# iorx610 register map
Registers from a debugger description file.
Registers are 8-bit, access not given, no defined reset value unless marked. A register's access mark holds for its fields unless they carry their own. Addresses are absolute; registers are grouped by the start of their names; lines under a group give offsets from that group; [hi:lo] are bit positions; {n}, {i} and the like mark numbered series; 'fields as' and 'values as' point back to an identical list; <NAME> marks a mode.

## SFR (part 1 of 2)
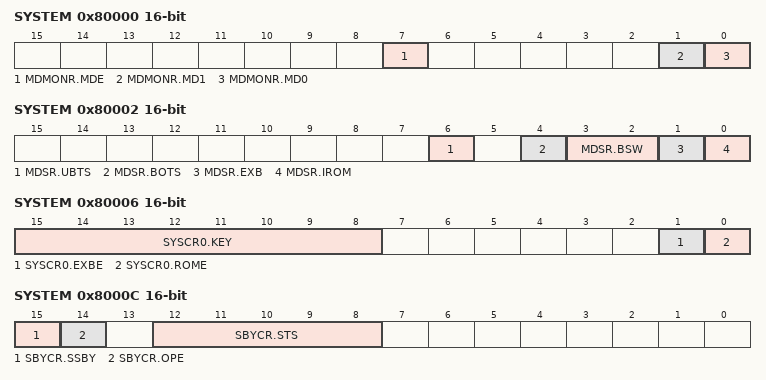
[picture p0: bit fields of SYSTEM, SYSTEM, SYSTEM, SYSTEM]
0x80000 SYSTEM 16-bit
  [7] MDMONR.MDE, [1] MDMONR.MD1, [0] MDMONR.MD0
0x80002 SYSTEM 16-bit
  [6] MDSR.UBTS, [4] MDSR.BOTS, [3:2] MDSR.BSW, [1] MDSR.EXB, [0] MDSR.IROM
0x80006 SYSTEM 16-bit
  [15:8] SYSCR0.KEY, [1] SYSCR0.EXBE, [0] SYSCR0.ROME
0x80008 SYSTEM 16-bit
  [0] SYSCR1.RAME
0x8000C SYSTEM 16-bit
  [15] SBYCR.SSBY, [14] SBYCR.OPE, [12:8] SBYCR.STS
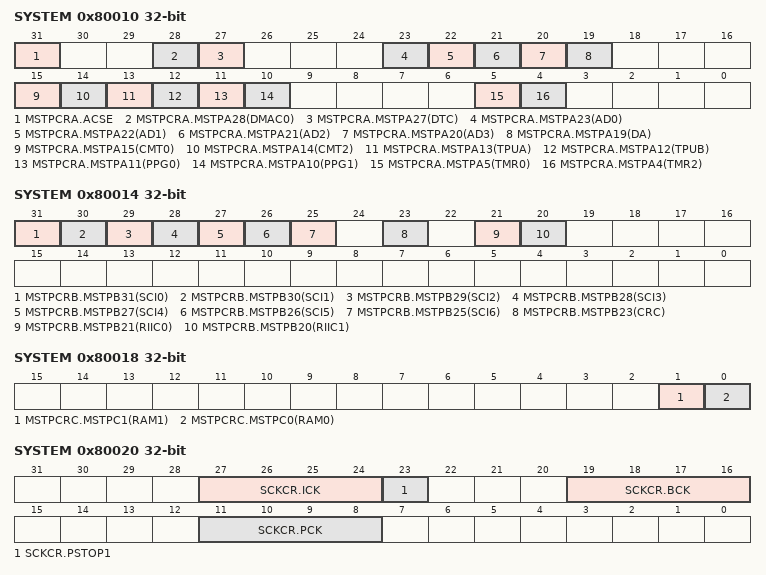
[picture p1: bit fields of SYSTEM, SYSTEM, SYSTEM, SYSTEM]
0x80010 SYSTEM 32-bit
  [31] MSTPCRA.ACSE, [28] MSTPCRA.MSTPA28(DMAC0), [27] MSTPCRA.MSTPA27(DTC), [23] MSTPCRA.MSTPA23(AD0), [22] MSTPCRA.MSTPA22(AD1), [21] MSTPCRA.MSTPA21(AD2), [20] MSTPCRA.MSTPA20(AD3), [19] MSTPCRA.MSTPA19(DA), [15] MSTPCRA.MSTPA15(CMT0), [14] MSTPCRA.MSTPA14(CMT2), [13] MSTPCRA.MSTPA13(TPUA), [12] MSTPCRA.MSTPA12(TPUB), [11] MSTPCRA.MSTPA11(PPG0), [10] MSTPCRA.MSTPA10(PPG1), [5] MSTPCRA.MSTPA5(TMR0), [4] MSTPCRA.MSTPA4(TMR2)
0x80014 SYSTEM 32-bit
  [31] MSTPCRB.MSTPB31(SCI0), [30] MSTPCRB.MSTPB30(SCI1), [29] MSTPCRB.MSTPB29(SCI2), [28] MSTPCRB.MSTPB28(SCI3), [27] MSTPCRB.MSTPB27(SCI4), [26] MSTPCRB.MSTPB26(SCI5), [25] MSTPCRB.MSTPB25(SCI6), [23] MSTPCRB.MSTPB23(CRC), [21] MSTPCRB.MSTPB21(RIIC0), [20] MSTPCRB.MSTPB20(RIIC1)
0x80018 SYSTEM 32-bit
  [1] MSTPCRC.MSTPC1(RAM1), [0] MSTPCRC.MSTPC0(RAM0)
0x80020 SYSTEM 32-bit
  [27:24] SCKCR.ICK, [23] SCKCR.PSTOP1, [19:16] SCKCR.BCK, [11:8] SCKCR.PCK
0x81300 BSC
  [0] BERCLR.STSCLR
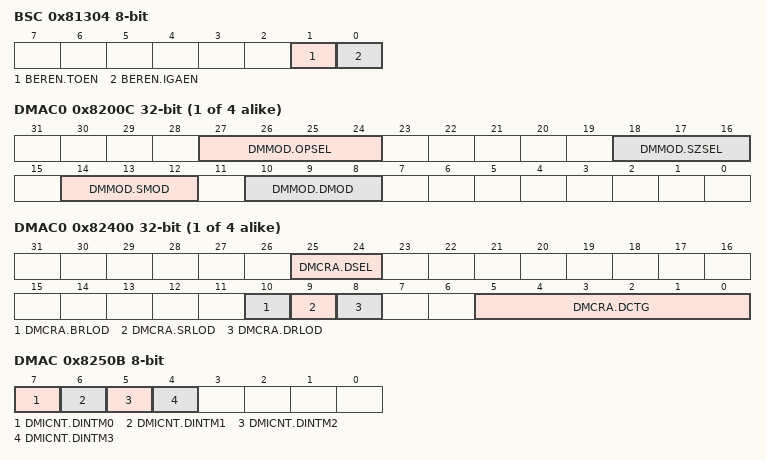
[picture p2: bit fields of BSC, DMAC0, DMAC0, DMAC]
0x81304 BSC
  [1] BEREN.TOEN, [0] BEREN.IGAEN
0x81306 BSC
  [0] BERIE.CPEN
{0x8200C+0x10*i} DMAC{i} 32-bit (i=0..3)
  [27:24] DMMOD.OPSEL, [18:16] DMMOD.SZSEL, [14:12] DMMOD.SMOD, [10:8] DMMOD.DMOD
{0x82400+8i} DMAC{i} 32-bit (i=0..3)
  [25:24] DMCRA.DSEL, [10] DMCRA.BRLOD, [9] DMCRA.SRLOD, [8] DMCRA.DRLOD, [5:0] DMCRA.DCTG
{0x82404+8i} DMAC{i} (i=0..3)
  [0] DMCRB.DSCLR
{0x82405+8i} DMAC{i} (i=0..3)
  [0] DMCRC.ECLR
{0x82406+8i} DMAC{i} (i=0..3)
  [0] DMCRD.DREQ
{0x82407+8i} DMAC{i} (i=0..3)
  [0] DMCRE.DEN
0x82502 DMAC
  [0] DMSCNT.DMST
0x8250B DMAC
  [7-n] DMICNT.DINTM{n} (n=0..3)
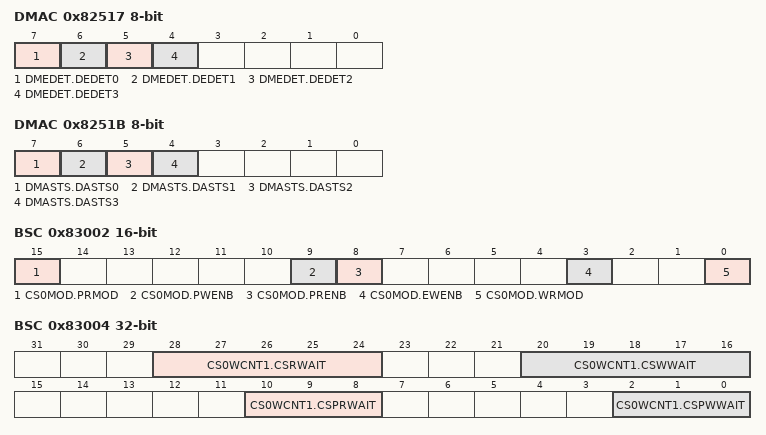
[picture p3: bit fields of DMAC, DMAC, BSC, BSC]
0x82517 DMAC
  [7-n] DMEDET.DEDET{n} (n=0..3)
0x8251B DMAC
  [7-n] DMASTS.DASTS{n} (n=0..3)
0x83002 BSC 16-bit
  [15] CS0MOD.PRMOD, [9] CS0MOD.PWENB, [8] CS0MOD.PRENB, [3] CS0MOD.EWENB, [0] CS0MOD.WRMOD
0x83004 BSC 32-bit
  [28:24] CS0WCNT1.CSRWAIT, [20:16] CS0WCNT1.CSWWAIT, [10:8] CS0WCNT1.CSPRWAIT, [2:0] CS0WCNT1.CSPWWAIT
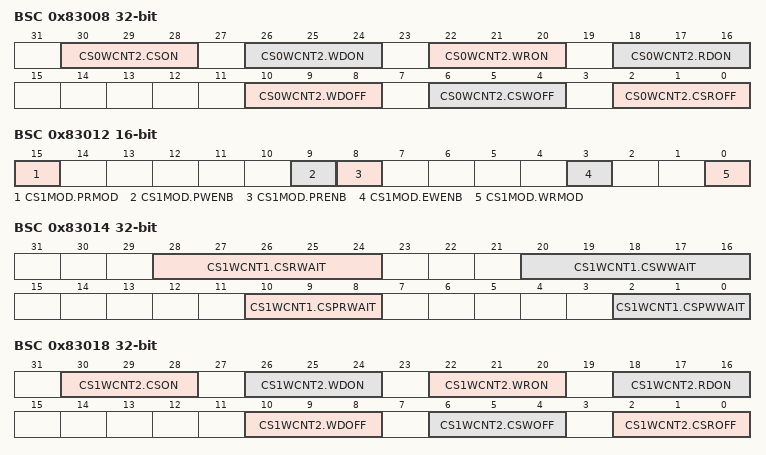
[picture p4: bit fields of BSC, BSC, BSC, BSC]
0x83008 BSC 32-bit
  [30:28] CS0WCNT2.CSON, [26:24] CS0WCNT2.WDON, [22:20] CS0WCNT2.WRON, [18:16] CS0WCNT2.RDON, [10:8] CS0WCNT2.WDOFF, [6:4] CS0WCNT2.CSWOFF, [2:0] CS0WCNT2.CSROFF
0x83012 BSC 16-bit
  [15] CS1MOD.PRMOD, [9] CS1MOD.PWENB, [8] CS1MOD.PRENB, [3] CS1MOD.EWENB, [0] CS1MOD.WRMOD
0x83014 BSC 32-bit
  [28:24] CS1WCNT1.CSRWAIT, [20:16] CS1WCNT1.CSWWAIT, [10:8] CS1WCNT1.CSPRWAIT, [2:0] CS1WCNT1.CSPWWAIT
0x83018 BSC 32-bit
  [30:28] CS1WCNT2.CSON, [26:24] CS1WCNT2.WDON, [22:20] CS1WCNT2.WRON, [18:16] CS1WCNT2.RDON, [10:8] CS1WCNT2.WDOFF, [6:4] CS1WCNT2.CSWOFF, [2:0] CS1WCNT2.CSROFF
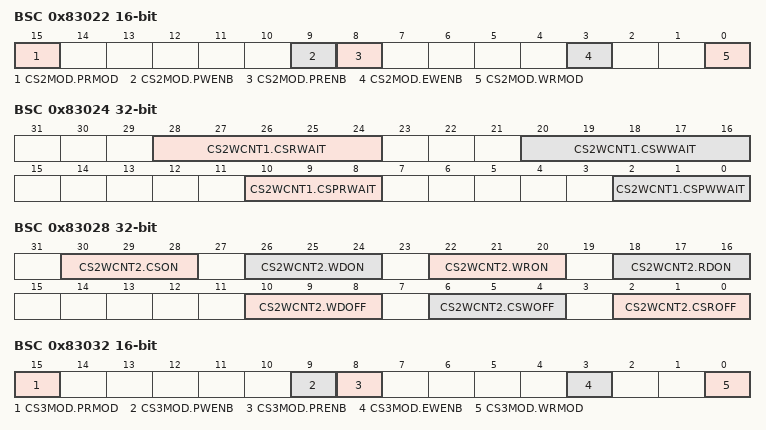
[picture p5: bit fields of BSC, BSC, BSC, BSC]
0x83022 BSC 16-bit
  [15] CS2MOD.PRMOD, [9] CS2MOD.PWENB, [8] CS2MOD.PRENB, [3] CS2MOD.EWENB, [0] CS2MOD.WRMOD
0x83024 BSC 32-bit
  [28:24] CS2WCNT1.CSRWAIT, [20:16] CS2WCNT1.CSWWAIT, [10:8] CS2WCNT1.CSPRWAIT, [2:0] CS2WCNT1.CSPWWAIT
0x83028 BSC 32-bit
  [30:28] CS2WCNT2.CSON, [26:24] CS2WCNT2.WDON, [22:20] CS2WCNT2.WRON, [18:16] CS2WCNT2.RDON, [10:8] CS2WCNT2.WDOFF, [6:4] CS2WCNT2.CSWOFF, [2:0] CS2WCNT2.CSROFF
0x83032 BSC 16-bit
  [15] CS3MOD.PRMOD, [9] CS3MOD.PWENB, [8] CS3MOD.PRENB, [3] CS3MOD.EWENB, [0] CS3MOD.WRMOD
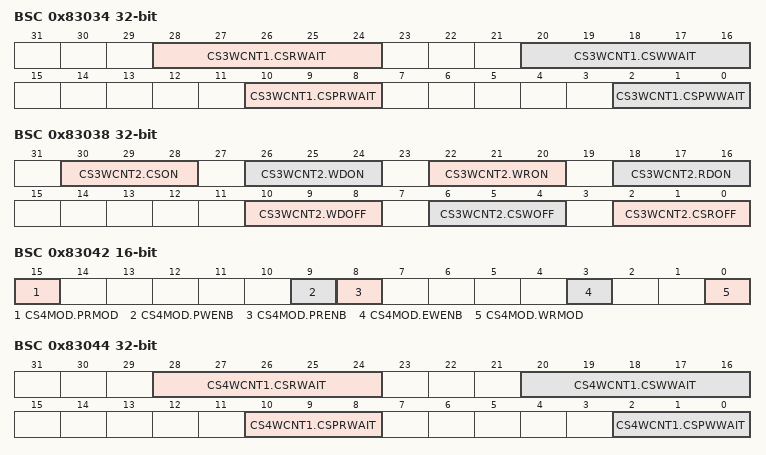
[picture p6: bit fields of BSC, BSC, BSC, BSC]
0x83034 BSC 32-bit
  [28:24] CS3WCNT1.CSRWAIT, [20:16] CS3WCNT1.CSWWAIT, [10:8] CS3WCNT1.CSPRWAIT, [2:0] CS3WCNT1.CSPWWAIT
0x83038 BSC 32-bit
  [30:28] CS3WCNT2.CSON, [26:24] CS3WCNT2.WDON, [22:20] CS3WCNT2.WRON, [18:16] CS3WCNT2.RDON, [10:8] CS3WCNT2.WDOFF, [6:4] CS3WCNT2.CSWOFF, [2:0] CS3WCNT2.CSROFF
0x83042 BSC 16-bit
  [15] CS4MOD.PRMOD, [9] CS4MOD.PWENB, [8] CS4MOD.PRENB, [3] CS4MOD.EWENB, [0] CS4MOD.WRMOD
0x83044 BSC 32-bit
  [28:24] CS4WCNT1.CSRWAIT, [20:16] CS4WCNT1.CSWWAIT, [10:8] CS4WCNT1.CSPRWAIT, [2:0] CS4WCNT1.CSPWWAIT
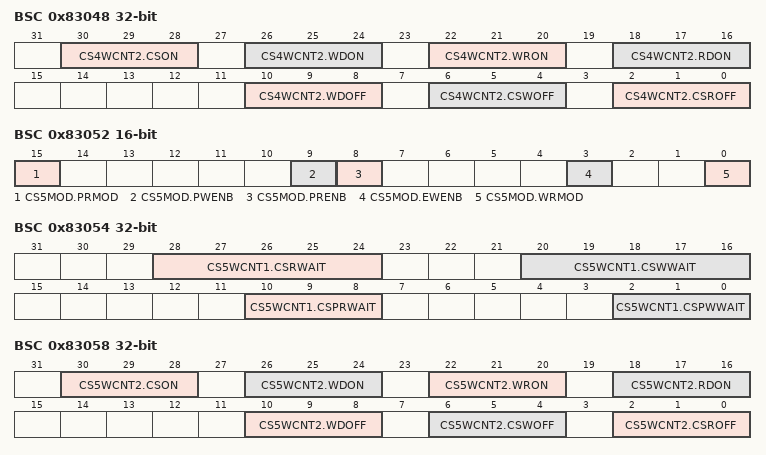
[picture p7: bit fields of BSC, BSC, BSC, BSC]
0x83048 BSC 32-bit
  [30:28] CS4WCNT2.CSON, [26:24] CS4WCNT2.WDON, [22:20] CS4WCNT2.WRON, [18:16] CS4WCNT2.RDON, [10:8] CS4WCNT2.WDOFF, [6:4] CS4WCNT2.CSWOFF, [2:0] CS4WCNT2.CSROFF
0x83052 BSC 16-bit
  [15] CS5MOD.PRMOD, [9] CS5MOD.PWENB, [8] CS5MOD.PRENB, [3] CS5MOD.EWENB, [0] CS5MOD.WRMOD
0x83054 BSC 32-bit
  [28:24] CS5WCNT1.CSRWAIT, [20:16] CS5WCNT1.CSWWAIT, [10:8] CS5WCNT1.CSPRWAIT, [2:0] CS5WCNT1.CSPWWAIT
0x83058 BSC 32-bit
  [30:28] CS5WCNT2.CSON, [26:24] CS5WCNT2.WDON, [22:20] CS5WCNT2.WRON, [18:16] CS5WCNT2.RDON, [10:8] CS5WCNT2.WDOFF, [6:4] CS5WCNT2.CSWOFF, [2:0] CS5WCNT2.CSROFF
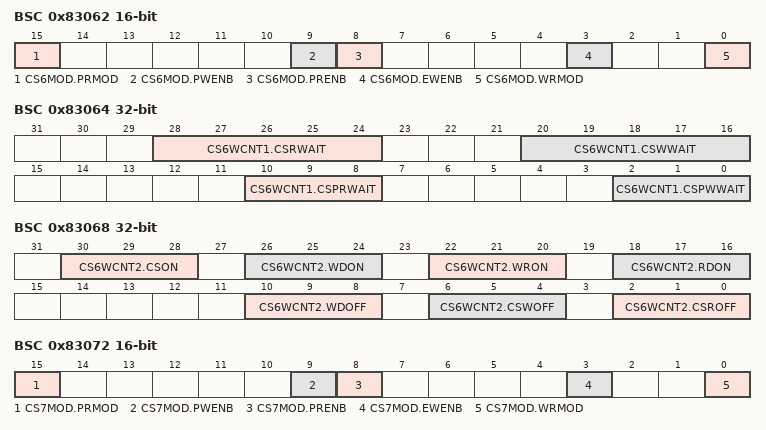
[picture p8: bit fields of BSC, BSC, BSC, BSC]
0x83062 BSC 16-bit
  [15] CS6MOD.PRMOD, [9] CS6MOD.PWENB, [8] CS6MOD.PRENB, [3] CS6MOD.EWENB, [0] CS6MOD.WRMOD
0x83064 BSC 32-bit
  [28:24] CS6WCNT1.CSRWAIT, [20:16] CS6WCNT1.CSWWAIT, [10:8] CS6WCNT1.CSPRWAIT, [2:0] CS6WCNT1.CSPWWAIT
0x83068 BSC 32-bit
  [30:28] CS6WCNT2.CSON, [26:24] CS6WCNT2.WDON, [22:20] CS6WCNT2.WRON, [18:16] CS6WCNT2.RDON, [10:8] CS6WCNT2.WDOFF, [6:4] CS6WCNT2.CSWOFF, [2:0] CS6WCNT2.CSROFF
0x83072 BSC 16-bit
  [15] CS7MOD.PRMOD, [9] CS7MOD.PWENB, [8] CS7MOD.PRENB, [3] CS7MOD.EWENB, [0] CS7MOD.WRMOD
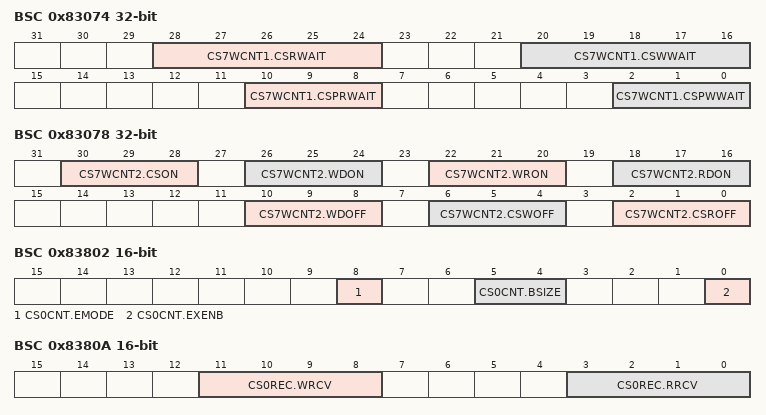
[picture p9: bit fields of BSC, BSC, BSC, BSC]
0x83074 BSC 32-bit
  [28:24] CS7WCNT1.CSRWAIT, [20:16] CS7WCNT1.CSWWAIT, [10:8] CS7WCNT1.CSPRWAIT, [2:0] CS7WCNT1.CSPWWAIT
0x83078 BSC 32-bit
  [30:28] CS7WCNT2.CSON, [26:24] CS7WCNT2.WDON, [22:20] CS7WCNT2.WRON, [18:16] CS7WCNT2.RDON, [10:8] CS7WCNT2.WDOFF, [6:4] CS7WCNT2.CSWOFF, [2:0] CS7WCNT2.CSROFF
0x83802 BSC 16-bit
  [8] CS0CNT.EMODE, [5:4] CS0CNT.BSIZE, [0] CS0CNT.EXENB
0x8380A BSC 16-bit
  [11:8] CS0REC.WRCV, [3:0] CS0REC.RRCV
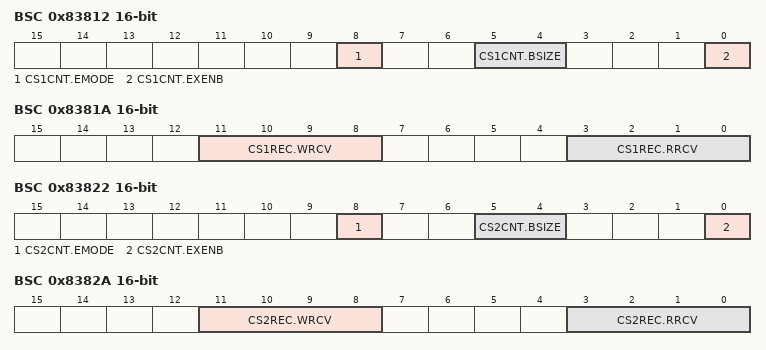
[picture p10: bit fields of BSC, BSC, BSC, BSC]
0x83812 BSC 16-bit
  [8] CS1CNT.EMODE, [5:4] CS1CNT.BSIZE, [0] CS1CNT.EXENB
0x8381A BSC 16-bit
  [11:8] CS1REC.WRCV, [3:0] CS1REC.RRCV
0x83822 BSC 16-bit
  [8] CS2CNT.EMODE, [5:4] CS2CNT.BSIZE, [0] CS2CNT.EXENB
0x8382A BSC 16-bit
  [11:8] CS2REC.WRCV, [3:0] CS2REC.RRCV
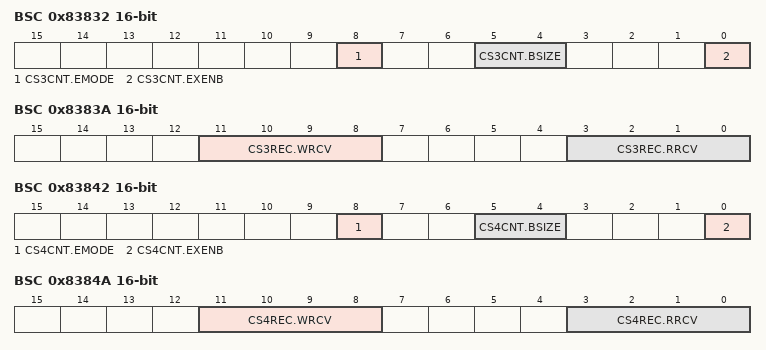
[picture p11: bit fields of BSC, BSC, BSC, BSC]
0x83832 BSC 16-bit
  [8] CS3CNT.EMODE, [5:4] CS3CNT.BSIZE, [0] CS3CNT.EXENB
0x8383A BSC 16-bit
  [11:8] CS3REC.WRCV, [3:0] CS3REC.RRCV
0x83842 BSC 16-bit
  [8] CS4CNT.EMODE, [5:4] CS4CNT.BSIZE, [0] CS4CNT.EXENB
0x8384A BSC 16-bit
  [11:8] CS4REC.WRCV, [3:0] CS4REC.RRCV
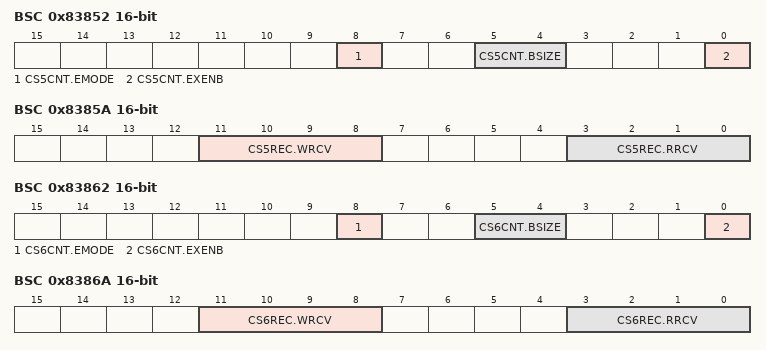
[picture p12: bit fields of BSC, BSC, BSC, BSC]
0x83852 BSC 16-bit
  [8] CS5CNT.EMODE, [5:4] CS5CNT.BSIZE, [0] CS5CNT.EXENB
0x8385A BSC 16-bit
  [11:8] CS5REC.WRCV, [3:0] CS5REC.RRCV
0x83862 BSC 16-bit
  [8] CS6CNT.EMODE, [5:4] CS6CNT.BSIZE, [0] CS6CNT.EXENB
0x8386A BSC 16-bit
  [11:8] CS6REC.WRCV, [3:0] CS6REC.RRCV
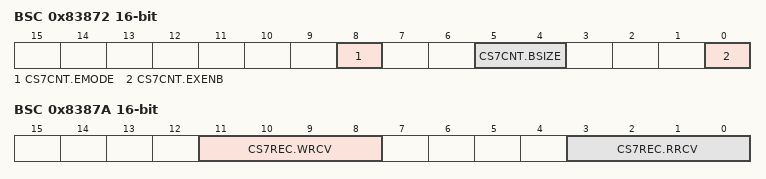
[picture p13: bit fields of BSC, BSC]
0x83872 BSC 16-bit
  [8] CS7CNT.EMODE, [5:4] CS7CNT.BSIZE, [0] CS7CNT.EXENB
0x8387A BSC 16-bit
  [11:8] CS7REC.WRCV, [3:0] CS7REC.RRCV
0x87000 ICU
  [0] IR[0].IR
0x87001 ICU
  [0] IR[1].IR
0x87002 ICU
  [0] IR[2].IR
0x87003 ICU
  [0] IR[3].IR
0x87004 ICU
  [0] IR[4].IR
0x87005 ICU
  [0] IR[5].IR
0x87006 ICU
  [0] IR[6].IR
0x87007 ICU
  [0] IR[7].IR
0x87008 ICU
  [0] IR[8].IR
0x87009 ICU
  [0] IR[9].IR
0x8700A ICU
  [0] IR[10].IR
0x8700B ICU
  [0] IR[11].IR
0x8700C ICU
  [0] IR[12].IR
0x8700D ICU
  [0] IR[13].IR
0x8700E ICU
  [0] IR[14].IR
0x8700F ICU
  [0] IR[15].IR
0x87010 ICU
  [0] IR[16](BSC,BUSERR).IR
0x87011 ICU
  [0] IR[17].IR
0x87012 ICU
  [0] IR[18].IR
0x87013 ICU
  [0] IR[19].IR
0x87014 ICU
  [0] IR[20].IR
0x87015 ICU
  [0] IR[21](FCU,FIFERR).IR
0x87016 ICU
  [0] IR[22].IR
0x87017 ICU
  [0] IR[23](FCU,FRDYI).IR
0x87018 ICU
  [0] IR[24].IR
0x87019 ICU
  [0] IR[25].IR
0x8701A ICU
  [0] IR[26].IR
0x8701B ICU
  [0] IR[27].IR
0x8701C ICU
  [0] IR[28](CMT0,CMI0).IR
0x8701D ICU
  [0] IR[29](CMT1,CMI1).IR
0x8701E ICU
  [0] IR[30](CMT2,CMI2).IR
0x8701F ICU
  [0] IR[31](CMT3,CMI3).IR
0x87020 ICU
  [0] IR[32].IR
0x87021 ICU
  [0] IR[33].IR
0x87022 ICU
  [0] IR[34].IR
0x87023 ICU
  [0] IR[35].IR
0x87024 ICU
  [0] IR[36].IR
0x87025 ICU
  [0] IR[37].IR
0x87026 ICU
  [0] IR[38].IR
0x87027 ICU
  [0] IR[39].IR
0x87028 ICU
  [0] IR[40].IR
0x87029 ICU
  [0] IR[41].IR
0x8702A ICU
  [0] IR[42].IR
0x8702B ICU
  [0] IR[43].IR
0x8702C ICU
  [0] IR[44].IR
0x8702D ICU
  [0] IR[45].IR
0x8702E ICU
  [0] IR[46].IR
0x8702F ICU
  [0] IR[47].IR
0x87030 ICU
  [0] IR[48].IR
0x87031 ICU
  [0] IR[49].IR
0x87032 ICU
  [0] IR[50].IR
0x87033 ICU
  [0] IR[51].IR
0x87034 ICU
  [0] IR[52].IR
0x87035 ICU
  [0] IR[53].IR
0x87036 ICU
  [0] IR[54].IR
0x87037 ICU
  [0] IR[55].IR
0x87038 ICU
  [0] IR[56].IR
0x87039 ICU
  [0] IR[57].IR
0x8703A ICU
  [0] IR[58].IR
0x8703B ICU
  [0] IR[59].IR
0x8703C ICU
  [0] IR[60].IR
0x8703D ICU
  [0] IR[61].IR
0x8703E ICU
  [0] IR[62].IR
0x8703F ICU
  [0] IR[63].IR
0x87040 ICU
  [0] IR[64](ICU,IRQ0).IR
0x87041 ICU
  [0] IR[65](ICU,IRQ1).IR
0x87042 ICU
  [0] IR[66](ICU,IRQ2).IR
0x87043 ICU
  [0] IR[67](ICU,IRQ3).IR
0x87044 ICU
  [0] IR[68](ICU,IRQ4).IR
0x87045 ICU
  [0] IR[69](ICU,IRQ5).IR
0x87046 ICU
  [0] IR[70](ICU,IRQ6).IR
0x87047 ICU
  [0] IR[71](ICU,IRQ7).IR
0x87048 ICU
  [0] IR[72](ICU,IRQ8).IR
0x87049 ICU
  [0] IR[73](ICU,IRQ9).IR
0x8704A ICU
  [0] IR[74](ICU,IRQ10).IR
0x8704B ICU
  [0] IR[75](ICU,IRQ11).IR
0x8704C ICU
  [0] IR[76](ICU,IRQ12).IR
0x8704D ICU
  [0] IR[77](ICU,IRQ13).IR
0x8704E ICU
  [0] IR[78](ICU,IRQ14).IR
0x8704F ICU
  [0] IR[79](ICU,IRQ15).IR
0x87050 ICU
  [0] IR[80].IR
0x87051 ICU
  [0] IR[81].IR
0x87052 ICU
  [0] IR[82].IR
0x87053 ICU
  [0] IR[83].IR
0x87054 ICU
  [0] IR[84].IR
0x87055 ICU
  [0] IR[85].IR
0x87056 ICU
  [0] IR[86].IR
0x87057 ICU
  [0] IR[87].IR
0x87058 ICU
  [0] IR[88].IR
0x87059 ICU
  [0] IR[89].IR
0x8705A ICU
  [0] IR[90].IR
0x8705B ICU
  [0] IR[91].IR
0x8705C ICU
  [0] IR[92].IR
0x8705D ICU
  [0] IR[93].IR
0x8705E ICU
  [0] IR[94].IR
0x8705F ICU
  [0] IR[95].IR
0x87060 ICU
  [0] IR[96](WDT,WOVI).IR
0x87061 ICU
  [0] IR[97].IR
0x87062 ICU
  [0] IR[98](AD0,ADI0).IR
0x87063 ICU
  [0] IR[99](AD1,ADI1).IR
0x87064 ICU
  [0] IR[100](AD2,ADI2).IR
0x87065 ICU
  [0] IR[101](AD3,ADI3).IR
0x87066 ICU
  [0] IR[102].IR
0x87067 ICU
  [0] IR[103].IR
0x87068 ICU
  [0] IR[104](TPU0,TGI0A).IR
0x87069 ICU
  [0] IR[105](TPU0,TGI0B).IR
0x8706A ICU
  [0] IR[106](TPU0,TGI0C).IR
0x8706B ICU
  [0] IR[107](TPU0,TGI0D).IR
0x8706C ICU
  [0] IR[108](TPU0,TCI0V).IR
0x8706D ICU
  [0] IR[109].IR
0x8706E ICU
  [0] IR[110].IR
0x8706F ICU
  [0] IR[111](TPU1,TGI1A).IR
0x87070 ICU
  [0] IR[112](TPU1,TGI1B).IR
0x87071 ICU
  [0] IR[113].IR
0x87072 ICU
  [0] IR[114].IR
0x87073 ICU
  [0] IR[115](TPU1,TCI1V).IR
0x87074 ICU
  [0] IR[116](TPU1,TCI1U).IR
0x87075 ICU
  [0] IR[117](TPU2,TGI2A).IR
0x87076 ICU
  [0] IR[118](TPU2,TGI2B).IR
0x87077 ICU
  [0] IR[119].IR
0x87078 ICU
  [0] IR[120](TPU2,TCI2V).IR
0x87079 ICU
  [0] IR[121](TPU2,TCI2U).IR
0x8707A ICU
  [0] IR[122](TPU3,TGI3A).IR
0x8707B ICU
  [0] IR[123](TPU3,TGI3B).IR
0x8707C ICU
  [0] IR[124](TPU3,TGI3C).IR
0x8707D ICU
  [0] IR[125](TPU3,TGI3D).IR
0x8707E ICU
  [0] IR[126](TPU3,TCI3V).IR
0x8707F ICU
  [0] IR[127](TPU4,TGI4A).IR
0x87080 ICU
  [0] IR[128](TPU4,TGI4B).IR
0x87081 ICU
  [0] IR[129].IR
0x87082 ICU
  [0] IR[130].IR
0x87083 ICU
  [0] IR[131](TPU4,TCI4V).IR
0x87084 ICU
  [0] IR[132](TPU4,TCI4U).IR
0x87085 ICU
  [0] IR[133](TPU5,TGI5A).IR
0x87086 ICU
  [0] IR[134](TPU5,TGI5B).IR
0x87087 ICU
  [0] IR[135].IR
0x87088 ICU
  [0] IR[136](TPU5,TCI5V).IR
0x87089 ICU
  [0] IR[137](TPU5,TCI5U).IR
0x8708A ICU
  [0] IR[138](TPU6,TGI6A).IR
0x8708B ICU
  [0] IR[139](TPU6,TGI6B).IR
0x8708C ICU
  [0] IR[140](TPU6,TGI6C).IR
0x8708D ICU
  [0] IR[141](TPU6,TGI6D).IR
0x8708E ICU
  [0] IR[142](TPU6,TCI6V).IR
0x8708F ICU
  [0] IR[143].IR
0x87090 ICU
  [0] IR[144].IR
0x87091 ICU
  [0] IR[145](TPU7,TGI7A).IR
0x87092 ICU
  [0] IR[146](TPU7,TGI7B).IR
0x87093 ICU
  [0] IR[147].IR
0x87094 ICU
  [0] IR[148].IR
0x87095 ICU
  [0] IR[149](TPU7,TCI7V).IR
0x87096 ICU
  [0] IR[150](TPU7,TCI7U).IR
0x87097 ICU
  [0] IR[151](TPU8,TGI8A).IR
0x87098 ICU
  [0] IR[152](TPU8,TGI8B).IR
0x87099 ICU
  [0] IR[153].IR
0x8709A ICU
  [0] IR[154](TPU8,TCI8V).IR
0x8709B ICU
  [0] IR[155](TPU8,TCI8U).IR
0x8709C ICU
  [0] IR[156](TPU9,TGI9A).IR
0x8709D ICU
  [0] IR[157](TPU9,TGI9B).IR
0x8709E ICU
  [0] IR[158](TPU9,TGI9C).IR
0x8709F ICU
  [0] IR[159](TPU9,TGI9D).IR
0x870A0 ICU
  [0] IR[160](TPU9,TCI9V).IR
0x870A1 ICU
  [0] IR[161](TPU10,TGI10A).IR
0x870A2 ICU
  [0] IR[162](TPU10,TGI10B).IR
0x870A3 ICU
  [0] IR[163].IR
0x870A4 ICU
  [0] IR[164].IR
0x870A5 ICU
  [0] IR[165](TPU10,TCI10V).IR
0x870A6 ICU
  [0] IR[166](TPU10,TCI10U).IR
0x870A7 ICU
  [0] IR[167](TPU11,TGI11A).IR
0x870A8 ICU
  [0] IR[168](TPU11,TGI11B).IR
0x870A9 ICU
  [0] IR[169].IR
0x870AA ICU
  [0] IR[170](TPU11,TCI11V).IR
0x870AB ICU
  [0] IR[171](TPU11,TCI11U).IR
0x870AC ICU
  [0] IR[172].IR
0x870AD ICU
  [0] IR[173].IR
0x870AE ICU
  [0] IR[174](TMR0,CMIA0).IR
0x870AF ICU
  [0] IR[175](TMR0,CMIB0).IR
0x870B0 ICU
  [0] IR[176](TMR0,OVI0).IR
0x870B1 ICU
  [0] IR[177](TMR1,CMIA1).IR
0x870B2 ICU
  [0] IR[178](TMR1,CMIB1).IR
0x870B3 ICU
  [0] IR[179](TMR1,OVI1).IR
0x870B4 ICU
  [0] IR[180](TMR2,CMIA2).IR
0x870B5 ICU
  [0] IR[181](TMR2,CMIB2).IR
0x870B6 ICU
  [0] IR[182](TMR2,OVI2).IR
0x870B7 ICU
  [0] IR[183](TMR3,CMIA3).IR
0x870B8 ICU
  [0] IR[184](TMR3,CMIB3).IR
0x870B9 ICU
  [0] IR[185](TMR3,OVI3).IR
0x870BA ICU
  [0] IR[186].IR
0x870BB ICU
  [0] IR[187].IR
0x870BC ICU
  [0] IR[188].IR
0x870BD ICU
  [0] IR[189].IR
0x870BE ICU
  [0] IR[190].IR
0x870BF ICU
  [0] IR[191].IR
0x870C0 ICU
  [0] IR[192].IR
0x870C1 ICU
  [0] IR[193].IR
0x870C2 ICU
  [0] IR[194].IR
0x870C3 ICU
  [0] IR[195].IR
0x870C4 ICU
  [0] IR[196].IR
0x870C5 ICU
  [0] IR[197].IR
0x870C6 ICU
  [0] IR[198](DMAC,DMTEND0).IR
0x870C7 ICU
  [0] IR[199](DMAC,DMTEND1).IR
0x870C8 ICU
  [0] IR[200](DMAC,DMTEND2).IR
0x870C9 ICU
  [0] IR[201](DMAC,DMTEND3).IR
0x870CA ICU
  [0] IR[202].IR
0x870CB ICU
  [0] IR[203].IR
0x870CC ICU
  [0] IR[204].IR
0x870CD ICU
  [0] IR[205].IR
0x870CE ICU
  [0] IR[206].IR
0x870CF ICU
  [0] IR[207].IR
0x870D0 ICU
  [0] IR[208].IR
0x870D1 ICU
  [0] IR[209].IR
0x870D2 ICU
  [0] IR[210].IR
0x870D3 ICU
  [0] IR[211].IR
0x870D4 ICU
  [0] IR[212].IR
0x870D5 ICU
  [0] IR[213].IR
0x870D6 ICU
  [0] IR[214](SCI0,ERI0).IR
0x870D7 ICU
  [0] IR[215](SCI0,RXI0).IR
0x870D8 ICU
  [0] IR[216](SCI0,TXI0).IR
0x870D9 ICU
  [0] IR[217](SCI0,TEI0).IR
0x870DA ICU
  [0] IR[218](SCI1,ERI1).IR
0x870DB ICU
  [0] IR[219](SCI1,RXI1).IR
0x870DC ICU
  [0] IR[220](SCI1,TXI1).IR
0x870DD ICU
  [0] IR[221](SCI1,TEI1).IR
0x870DE ICU
  [0] IR[222](SCI2,ERI2).IR
0x870DF ICU
  [0] IR[223](SCI2,RXI2).IR
0x870E0 ICU
  [0] IR[224](SCI2,TXI2).IR
0x870E1 ICU
  [0] IR[225](SCI2,TEI2).IR
0x870E2 ICU
  [0] IR[226](SCI3,ERI3).IR
0x870E3 ICU
  [0] IR[227](SCI3,RXI3).IR
0x870E4 ICU
  [0] IR[228](SCI3,TXI3).IR
0x870E5 ICU
  [0] IR[229](SCI3,TEI3).IR
0x870E6 ICU
  [0] IR[230](SCI4,ERI4).IR
0x870E7 ICU
  [0] IR[231](SCI4,RXI4).IR
0x870E8 ICU
  [0] IR[232](SCI4,TXI4).IR
0x870E9 ICU
  [0] IR[233](SCI4,TEI4).IR
0x870EA ICU
  [0] IR[234](SCI5,ERI5).IR
0x870EB ICU
  [0] IR[235](SCI5,RXI5).IR
0x870EC ICU
  [0] IR[236](SCI5,TXI5).IR
0x870ED ICU
  [0] IR[237](SCI5,TEI5).IR
0x870EE ICU
  [0] IR[238](SCI6,ERI6).IR
0x870EF ICU
  [0] IR[239](SCI6,RXI6).IR
0x870F0 ICU
  [0] IR[240](SCI6,TXI6).IR
0x870F1 ICU
  [0] IR[241](SCI6,TEI6).IR
0x870F2 ICU
  [0] IR[242].IR
0x870F3 ICU
  [0] IR[243].IR
0x870F4 ICU
  [0] IR[244].IR
0x870F5 ICU
  [0] IR[245].IR
0x870F6 ICU
  [0] IR[246](RIIC0,ICEEI0).IR
0x870F7 ICU
  [0] IR[247](RIIC0,ICRXI0).IR
0x870F8 ICU
  [0] IR[248](RIIC0,ICTXI0).IR
0x870F9 ICU
  [0] IR[249](RIIC0,ICTEI0).IR
0x870FA ICU
  [0] IR[250](RIIC1,ICEEI1).IR
0x870FB ICU
  [0] IR[251](RIIC1,ICRXI1).IR
0x870FC ICU
  [0] IR[252](RIIC1,ICTXI1).IR
0x870FD ICU
  [0] IR[253].IR
0x870FE ICU
  [0] IR[254].IR
0x87100 ICU
  [1:0] ISELR[0].ISEL
0x87101 ICU
  [1:0] ISELR[1].ISEL
0x87102 ICU
  [1:0] ISELR[2].ISEL
0x87103 ICU
  [1:0] ISELR[3].ISEL
0x87104 ICU
  [1:0] ISELR[4].ISEL
0x87105 ICU
  [1:0] ISELR[5].ISEL
0x87106 ICU
  [1:0] ISELR[6].ISEL
0x87107 ICU
  [1:0] ISELR[7].ISEL
0x87108 ICU
  [1:0] ISELR[8].ISEL
0x87109 ICU
  [1:0] ISELR[9].ISEL
0x8710A ICU
  [1:0] ISELR[10].ISEL
0x8710B ICU
  [1:0] ISELR[11].ISEL
0x8710C ICU
  [1:0] ISELR[12].ISEL
0x8710D ICU
  [1:0] ISELR[13].ISEL
0x8710E ICU
  [1:0] ISELR[14].ISEL
0x8710F ICU
  [1:0] ISELR[15].ISEL
0x87110 ICU
  [1:0] ISELR[16](BSC,BUSERR).ISEL
0x87111 ICU
  [1:0] ISELR[17].ISEL
0x87112 ICU
  [1:0] ISELR[18].ISEL
0x87113 ICU
  [1:0] ISELR[19].ISEL
0x87114 ICU
  [1:0] ISELR[20].ISEL
0x87115 ICU
  [1:0] ISELR[21](FCU,FIFERR).ISEL
0x87116 ICU
  [1:0] ISELR[22].ISEL
0x87117 ICU
  [1:0] ISELR[23](FCU,FRDYI).ISEL
0x87118 ICU
  [1:0] ISELR[24].ISEL
0x87119 ICU
  [1:0] ISELR[25].ISEL
0x8711A ICU
  [1:0] ISELR[26].ISEL
0x8711B ICU
  [1:0] ISELR[27].ISEL
0x8711C ICU
  [1:0] ISELR[28](CMT0,CMI0).ISEL
0x8711D ICU
  [1:0] ISELR[29](CMT1,CMI1).ISEL
0x8711E ICU
  [1:0] ISELR[30](CMT2,CMI2).ISEL
0x8711F ICU
  [1:0] ISELR[31](CMT3,CMI3).ISEL
0x87120 ICU
  [1:0] ISELR[32].ISEL
0x87121 ICU
  [1:0] ISELR[33].ISEL
0x87122 ICU
  [1:0] ISELR[34].ISEL
0x87123 ICU
  [1:0] ISELR[35].ISEL
0x87124 ICU
  [1:0] ISELR[36].ISEL
0x87125 ICU
  [1:0] ISELR[37].ISEL
0x87126 ICU
  [1:0] ISELR[38].ISEL
0x87127 ICU
  [1:0] ISELR[39].ISEL
0x87128 ICU
  [1:0] ISELR[40].ISEL
0x87129 ICU
  [1:0] ISELR[41].ISEL
0x8712A ICU
  [1:0] ISELR[42].ISEL
0x8712B ICU
  [1:0] ISELR[43].ISEL
0x8712C ICU
  [1:0] ISELR[44].ISEL
0x8712D ICU
  [1:0] ISELR[45].ISEL
0x8712E ICU
  [1:0] ISELR[46].ISEL
0x8712F ICU
  [1:0] ISELR[47].ISEL
0x87130 ICU
  [1:0] ISELR[48].ISEL
0x87131 ICU
  [1:0] ISELR[49].ISEL
0x87132 ICU
  [1:0] ISELR[50].ISEL
0x87133 ICU
  [1:0] ISELR[51].ISEL
0x87134 ICU
  [1:0] ISELR[52].ISEL
0x87135 ICU
  [1:0] ISELR[53].ISEL
0x87136 ICU
  [1:0] ISELR[54].ISEL
0x87137 ICU
  [1:0] ISELR[55].ISEL
0x87138 ICU
  [1:0] ISELR[56].ISEL
0x87139 ICU
  [1:0] ISELR[57].ISEL
0x8713A ICU
  [1:0] ISELR[58].ISEL
0x8713B ICU
  [1:0] ISELR[59].ISEL
0x8713C ICU
  [1:0] ISELR[60].ISEL
0x8713D ICU
  [1:0] ISELR[61].ISEL
0x8713E ICU
  [1:0] ISELR[62].ISEL
0x8713F ICU
  [1:0] ISELR[63].ISEL
0x87140 ICU
  [1:0] ISELR[64](ICU,IRQ0).ISEL
0x87141 ICU
  [1:0] ISELR[65](ICU,IRQ1).ISEL
0x87142 ICU
  [1:0] ISELR[66](ICU,IRQ2).ISEL
0x87143 ICU
  [1:0] ISELR[67](ICU,IRQ3).ISEL
0x87144 ICU
  [1:0] ISELR[68](ICU,IRQ4).ISEL
0x87145 ICU
  [1:0] ISELR[69](ICU,IRQ5).ISEL
0x87146 ICU
  [1:0] ISELR[70](ICU,IRQ6).ISEL
0x87147 ICU
  [1:0] ISELR[71](ICU,IRQ7).ISEL
0x87148 ICU
  [1:0] ISELR[72](ICU,IRQ8).ISEL
0x87149 ICU
  [1:0] ISELR[73](ICU,IRQ9).ISEL
0x8714A ICU
  [1:0] ISELR[74](ICU,IRQ10).ISEL
0x8714B ICU
  [1:0] ISELR[75](ICU,IRQ11).ISEL
0x8714C ICU
  [1:0] ISELR[76](ICU,IRQ12).ISEL
0x8714D ICU
  [1:0] ISELR[77](ICU,IRQ13).ISEL
0x8714E ICU
  [1:0] ISELR[78](ICU,IRQ14).ISEL
0x8714F ICU
  [1:0] ISELR[79](ICU,IRQ15).ISEL
0x87150 ICU
  [1:0] ISELR[80].ISEL
0x87151 ICU
  [1:0] ISELR[81].ISEL
0x87152 ICU
  [1:0] ISELR[82].ISEL
0x87153 ICU
  [1:0] ISELR[83].ISEL
0x87154 ICU
  [1:0] ISELR[84].ISEL
0x87155 ICU
  [1:0] ISELR[85].ISEL
0x87156 ICU
  [1:0] ISELR[86].ISEL
0x87157 ICU
  [1:0] ISELR[87].ISEL
0x87158 ICU
  [1:0] ISELR[88].ISEL
0x87159 ICU
  [1:0] ISELR[89].ISEL
0x8715A ICU
  [1:0] ISELR[90].ISEL
0x8715B ICU
  [1:0] ISELR[91].ISEL
0x8715C ICU
  [1:0] ISELR[92].ISEL
0x8715D ICU
  [1:0] ISELR[93].ISEL
0x8715E ICU
  [1:0] ISELR[94].ISEL
0x8715F ICU
  [1:0] ISELR[95].ISEL
0x87160 ICU
  [1:0] ISELR[96](WDT,WOVI).ISEL
0x87161 ICU
  [1:0] ISELR[97].ISEL
0x87162 ICU
  [1:0] ISELR[98](AD0,ADI0).ISEL
0x87163 ICU
  [1:0] ISELR[99](AD1,ADI1).ISEL
0x87164 ICU
  [1:0] ISELR[100](AD2,ADI2).ISEL
0x87165 ICU
  [1:0] ISELR[101](AD3,ADI3).ISEL
0x87166 ICU
  [1:0] ISELR[102].ISEL
0x87167 ICU
  [1:0] ISELR[103].ISEL
0x87168 ICU
  [1:0] ISELR[104](TPU0,TGI0A).ISEL
0x87169 ICU
  [1:0] ISELR[105](TPU0,TGI0B).ISEL
0x8716A ICU
  [1:0] ISELR[106](TPU0,TGI0C).ISEL
0x8716B ICU
  [1:0] ISELR[107](TPU0,TGI0D).ISEL
0x8716C ICU
  [1:0] ISELR[108](TPU0,TCI0V).ISEL
0x8716D ICU
  [1:0] ISELR[109].ISEL
0x8716E ICU
  [1:0] ISELR[110].ISEL
0x8716F ICU
  [1:0] ISELR[111](TPU1,TGI1A).ISEL
0x87170 ICU
  [1:0] ISELR[112](TPU1,TGI1B).ISEL
0x87171 ICU
  [1:0] ISELR[113].ISEL
0x87172 ICU
  [1:0] ISELR[114].ISEL
0x87173 ICU
  [1:0] ISELR[115](TPU1,TCI1V).ISEL
0x87174 ICU
  [1:0] ISELR[116](TPU1,TCI1U).ISEL
0x87175 ICU
  [1:0] ISELR[117](TPU2,TGI2A).ISEL
0x87176 ICU
  [1:0] ISELR[118](TPU2,TGI2B).ISEL
0x87177 ICU
  [1:0] ISELR[119].ISEL
0x87178 ICU
  [1:0] ISELR[120](TPU2,TCI2V).ISEL
0x87179 ICU
  [1:0] ISELR[121](TPU2,TCI2U).ISEL
0x8717A ICU
  [1:0] ISELR[122](TPU3,TGI3A).ISEL
0x8717B ICU
  [1:0] ISELR[123](TPU3,TGI3B).ISEL
0x8717C ICU
  [1:0] ISELR[124](TPU3,TGI3C).ISEL
0x8717D ICU
  [1:0] ISELR[125](TPU3,TGI3D).ISEL
0x8717E ICU
  [1:0] ISELR[126](TPU3,TCI3V).ISEL
0x8717F ICU
  [1:0] ISELR[127](TPU4,TGI4A).ISEL
0x87180 ICU
  [1:0] ISELR[128](TPU4,TGI4B).ISEL
0x87181 ICU
  [1:0] ISELR[129].ISEL
0x87182 ICU
  [1:0] ISELR[130].ISEL
0x87183 ICU
  [1:0] ISELR[131](TPU4,TCI4V).ISEL
0x87184 ICU
  [1:0] ISELR[132](TPU4,TCI4U).ISEL
0x87185 ICU
  [1:0] ISELR[133](TPU5,TGI5A).ISEL
0x87186 ICU
  [1:0] ISELR[134](TPU5,TGI5B).ISEL
0x87187 ICU
  [1:0] ISELR[135].ISEL
0x87188 ICU
  [1:0] ISELR[136](TPU5,TCI5V).ISEL
0x87189 ICU
  [1:0] ISELR[137](TPU5,TCI5U).ISEL
0x8718A ICU
  [1:0] ISELR[138](TPU6,TGI6A).ISEL
0x8718B ICU
  [1:0] ISELR[139](TPU6,TGI6B).ISEL
0x8718C ICU
  [1:0] ISELR[140](TPU6,TGI6C).ISEL
0x8718D ICU
  [1:0] ISELR[141](TPU6,TGI6D).ISEL
0x8718E ICU
  [1:0] ISELR[142](TPU6,TCI6V).ISEL
0x8718F ICU
  [1:0] ISELR[143].ISEL
0x87190 ICU
  [1:0] ISELR[144].ISEL
0x87191 ICU
  [1:0] ISELR[145](TPU7,TGI7A).ISEL
0x87192 ICU
  [1:0] ISELR[146](TPU7,TGI7B).ISEL
0x87193 ICU
  [1:0] ISELR[147].ISEL
0x87194 ICU
  [1:0] ISELR[148].ISEL
0x87195 ICU
  [1:0] ISELR[149](TPU7,TCI7V).ISEL
0x87196 ICU
  [1:0] ISELR[150](TPU7,TCI7U).ISEL
0x87197 ICU
  [1:0] ISELR[151](TPU8,TGI8A).ISEL
0x87198 ICU
  [1:0] ISELR[152](TPU8,TGI8B).ISEL
0x87199 ICU
  [1:0] ISELR[153].ISEL
0x8719A ICU
  [1:0] ISELR[154](TPU8,TCI8V).ISEL
0x8719B ICU
  [1:0] ISELR[155](TPU8,TCI8U).ISEL
0x8719C ICU
  [1:0] ISELR[156](TPU9,TGI9A).ISEL
0x8719D ICU
  [1:0] ISELR[157](TPU9,TGI9B).ISEL
0x8719E ICU
  [1:0] ISELR[158](TPU9,TGI9C).ISEL
0x8719F ICU
  [1:0] ISELR[159](TPU9,TGI9D).ISEL
0x871A0 ICU
  [1:0] ISELR[160](TPU9,TCI9V).ISEL
0x871A1 ICU
  [1:0] ISELR[161](TPU10,TGI10A).ISEL
0x871A2 ICU
  [1:0] ISELR[162](TPU10,TGI10B).ISEL
0x871A3 ICU
  [1:0] ISELR[163].ISEL
0x871A4 ICU
  [1:0] ISELR[164].ISEL
0x871A5 ICU
  [1:0] ISELR[165](TPU10,TCI10V).ISEL
0x871A6 ICU
  [1:0] ISELR[166](TPU10,TCI10U).ISEL
0x871A7 ICU
  [1:0] ISELR[167](TPU11,TGI11A).ISEL
0x871A8 ICU
  [1:0] ISELR[168](TPU11,TGI11B).ISEL
0x871A9 ICU
  [1:0] ISELR[169].ISEL
0x871AA ICU
  [1:0] ISELR[170](TPU11,TCI11V).ISEL
0x871AB ICU
  [1:0] ISELR[171](TPU11,TCI11U).ISEL
0x871AC ICU
  [1:0] ISELR[172].ISEL
0x871AD ICU
  [1:0] ISELR[173].ISEL
0x871AE ICU
  [1:0] ISELR[174](TMR0,CMIA0).ISEL
0x871AF ICU
  [1:0] ISELR[175](TMR0,CMIB0).ISEL
0x871B0 ICU
  [1:0] ISELR[176](TMR0,OVI0).ISEL
0x871B1 ICU
  [1:0] ISELR[177](TMR1,CMIA1).ISEL
0x871B2 ICU
  [1:0] ISELR[178](TMR1,CMIB1).ISEL
0x871B3 ICU
  [1:0] ISELR[179](TMR1,OVI1).ISEL
0x871B4 ICU
  [1:0] ISELR[180](TMR2,CMIA2).ISEL
0x871B5 ICU
  [1:0] ISELR[181](TMR2,CMIB2).ISEL
0x871B6 ICU
  [1:0] ISELR[182](TMR2,OVI2).ISEL
0x871B7 ICU
  [1:0] ISELR[183](TMR3,CMIA3).ISEL
0x871B8 ICU
  [1:0] ISELR[184](TMR3,CMIB3).ISEL
0x871B9 ICU
  [1:0] ISELR[185](TMR3,OVI3).ISEL
0x871BA ICU
  [1:0] ISELR[186].ISEL
0x871BB ICU
  [1:0] ISELR[187].ISEL
0x871BC ICU
  [1:0] ISELR[188].ISEL
0x871BD ICU
  [1:0] ISELR[189].ISEL
0x871BE ICU
  [1:0] ISELR[190].ISEL
0x871BF ICU
  [1:0] ISELR[191].ISEL
0x871C0 ICU
  [1:0] ISELR[192].ISEL
0x871C1 ICU
  [1:0] ISELR[193].ISEL
0x871C2 ICU
  [1:0] ISELR[194].ISEL
0x871C3 ICU
  [1:0] ISELR[195].ISEL
0x871C4 ICU
  [1:0] ISELR[196].ISEL
0x871C5 ICU
  [1:0] ISELR[197].ISEL
0x871C6 ICU
  [1:0] ISELR[198](DMAC,DMTEND0).ISEL
0x871C7 ICU
  [1:0] ISELR[199](DMAC,DMTEND1).ISEL
0x871C8 ICU
  [1:0] ISELR[200](DMAC,DMTEND2).ISEL
0x871C9 ICU
  [1:0] ISELR[201](DMAC,DMTEND3).ISEL
0x871CA ICU
  [1:0] ISELR[202].ISEL
0x871CB ICU
  [1:0] ISELR[203].ISEL
0x871CC ICU
  [1:0] ISELR[204].ISEL
0x871CD ICU
  [1:0] ISELR[205].ISEL
0x871CE ICU
  [1:0] ISELR[206].ISEL
0x871CF ICU
  [1:0] ISELR[207].ISEL
0x871D0 ICU
  [1:0] ISELR[208].ISEL
0x871D1 ICU
  [1:0] ISELR[209].ISEL
0x871D2 ICU
  [1:0] ISELR[210].ISEL
0x871D3 ICU
  [1:0] ISELR[211].ISEL
0x871D4 ICU
  [1:0] ISELR[212].ISEL
0x871D5 ICU
  [1:0] ISELR[213].ISEL
0x871D6 ICU
  [1:0] ISELR[214](SCI0,ERI0).ISEL
0x871D7 ICU
  [1:0] ISELR[215](SCI0,RXI0).ISEL
0x871D8 ICU
  [1:0] ISELR[216](SCI0,TXI0).ISEL
0x871D9 ICU
  [1:0] ISELR[217](SCI0,TEI0).ISEL
0x871DA ICU
  [1:0] ISELR[218](SCI1,ERI1).ISEL
0x871DB ICU
  [1:0] ISELR[219](SCI1,RXI1).ISEL
0x871DC ICU
  [1:0] ISELR[220](SCI1,TXI1).ISEL
0x871DD ICU
  [1:0] ISELR[221](SCI1,TEI1).ISEL
0x871DE ICU
  [1:0] ISELR[222](SCI2,ERI2).ISEL
0x871DF ICU
  [1:0] ISELR[223](SCI2,RXI2).ISEL
0x871E0 ICU
  [1:0] ISELR[224](SCI2,TXI2).ISEL
0x871E1 ICU
  [1:0] ISELR[225](SCI2,TEI2).ISEL
0x871E2 ICU
  [1:0] ISELR[226](SCI3,ERI3).ISEL
0x871E3 ICU
  [1:0] ISELR[227](SCI3,RXI3).ISEL
0x871E4 ICU
  [1:0] ISELR[228](SCI3,TXI3).ISEL
0x871E5 ICU
  [1:0] ISELR[229](SCI3,TEI3).ISEL
0x871E6 ICU
  [1:0] ISELR[230](SCI4,ERI4).ISEL
0x871E7 ICU
  [1:0] ISELR[231](SCI4,RXI4).ISEL
0x871E8 ICU
  [1:0] ISELR[232](SCI4,TXI4).ISEL
0x871E9 ICU
  [1:0] ISELR[233](SCI4,TEI4).ISEL
0x871EA ICU
  [1:0] ISELR[234](SCI5,ERI5).ISEL
0x871EB ICU
  [1:0] ISELR[235](SCI5,RXI5).ISEL
0x871EC ICU
  [1:0] ISELR[236](SCI5,TXI5).ISEL
0x871ED ICU
  [1:0] ISELR[237](SCI5,TEI5).ISEL
0x871EE ICU
  [1:0] ISELR[238](SCI6,ERI6).ISEL
0x871EF ICU
  [1:0] ISELR[239](SCI6,RXI6).ISEL
0x871F0 ICU
  [1:0] ISELR[240](SCI6,TXI6).ISEL
0x871F1 ICU
  [1:0] ISELR[241](SCI6,TEI6).ISEL
0x871F2 ICU
  [1:0] ISELR[242].ISEL
0x871F3 ICU
  [1:0] ISELR[243].ISEL
0x871F4 ICU
  [1:0] ISELR[244].ISEL
0x871F5 ICU
  [1:0] ISELR[245].ISEL
0x871F6 ICU
  [1:0] ISELR[246](RIIC0,ICEEI0).ISEL
0x871F7 ICU
  [1:0] ISELR[247](RIIC0,ICRXI0).ISEL
0x871F8 ICU
  [1:0] ISELR[248](RIIC0,ICTXI0).ISEL
0x871F9 ICU
  [1:0] ISELR[249](RIIC0,ICTEI0).ISEL
0x871FA ICU
  [1:0] ISELR[250](RIIC1,ICEEI1).ISEL
0x871FB ICU
  [1:0] ISELR[251](RIIC1,ICRXI1).ISEL
0x871FC ICU
  [1:0] ISELR[252](RIIC1,ICTXI1).ISEL
0x871FD ICU
  [1:0] ISELR[253].ISEL
